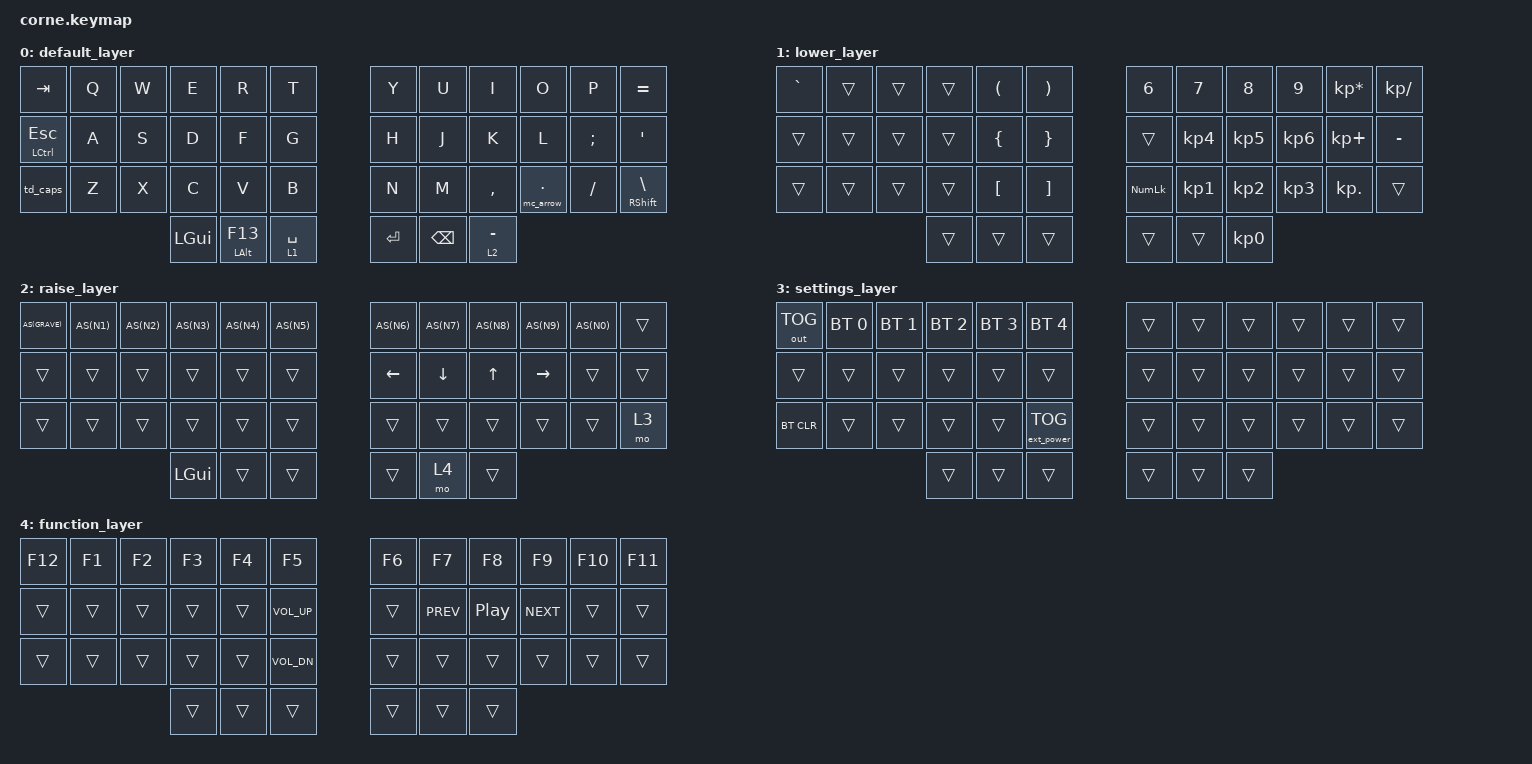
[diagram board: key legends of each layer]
/*
 * Copyright (c) 2020 The ZMK Contributors
 *
 * SPDX-License-Identifier: MIT
 */

#include <behaviors.dtsi>
#include <dt-bindings/zmk/keys.h>
#include <dt-bindings/zmk/bt.h>
#include <dt-bindings/zmk/outputs.h>
#include <dt-bindings/zmk/ext_power.h>

#define AS(keycode) &as LS(keycode) keycode

/ {
	behaviors {
		ht_arr: hold_tap_arrow {
			compatible = "zmk,behavior-hold-tap";
			label = "HT_ARR";
			#binding-cells = <2>;
			tapping-term-ms = <200>;
			flavor = "tap-preferred";
			bindings = <&mc_arrow>, <&kp>;
		};
		td_caps: tap_dance_caps_word {
			compatible = "zmk,behavior-tap-dance";
			label = "TD_CAPS";
			#binding-cells = <0>;
			tapping-term-ms = <150>;
			bindings = <&kp LSHFT>, <&caps_word>;
		};
		as: auto_shift {
			compatible = "zmk,behavior-hold-tap";
			label = "AUTO_SHIFT";
			#binding-cells = <2>;
			tapping_term_ms = <250>;
			quick_tap_ms = <0>;
			flavor = "tap-preferred";
			bindings = <&kp>, <&kp>;
		};
	};
	macros {
		ZMK_MACRO(mc_arrow,
			wait-ms = <50>;
			tap-ms = <50>;
			bindings 
				= <&macro_tap &kp MINUS>
				, <&macro_press &kp LSHFT>
				, <&macro_tap &kp DOT>
				, <&macro_release &kp LSHFT>
				;
		)
	};
	keymap {
		compatible = "zmk,keymap";

		default_layer {
			bindings = <
	&kp TAB      &kp Q &kp W &kp E &kp R &kp T	&kp Y &kp U &kp I     &kp O         &kp P    &kp EQUAL
	&mt LCTRL ESC &kp A &kp S &kp D &kp F &kp G	&kp H &kp J &kp K     &kp L         &kp SEMI &kp SQT
	&td_caps     &kp Z &kp X &kp C &kp V &kp B	&kp N &kp M &kp COMMA &ht_arr 0 DOT &kp FSLH &mt RSHFT BSLH
	        &kp LGUI &mt LALT F13 &lt 1 SPACE	&kp RET &kp BSPC &lt 2 MINUS
			>;
		};
		lower_layer {
			bindings = <
	&kp GRAVE &trans &trans &trans &kp LPAR &kp RPAR	&kp N6     &kp N7    &kp N8    &kp N9    &kp KP_MULTIPLY &kp KP_DIVIDE
	&trans    &trans &trans &trans &kp LBRC &kp RBRC	&trans     &kp KP_N4 &kp KP_N5 &kp KP_N6 &kp KP_PLUS     &kp MINUS
	&trans    &trans &trans &trans &kp LBKT &kp RBKT	&kp KP_NUM &kp KP_N1 &kp KP_N2 &kp KP_N3 &kp KP_DOT      &trans
	                            &trans &trans &trans	&trans     &trans    &kp KP_N0
			>;
		};

		raise_layer {
			bindings = <
	AS(GRAVE) AS(N1) AS(N2) AS(N3) AS(N4) AS(N5)	AS(N6)   AS(N7)   AS(N8) AS(N9)    AS(N0) &trans
	&trans    &trans &trans &trans &trans &trans	&kp LEFT &kp DOWN &kp UP &kp RIGHT &trans &trans
	&trans    &trans &trans &trans &trans &trans	&trans   &trans   &trans &trans    &trans &mo 3
	                      &kp LGUI &trans &trans	&trans   &mo 4    &trans
			>;
		};

		settings_layer {
			bindings = <
	&out OUT_TOG &bt BT_SEL 0 &bt BT_SEL 1 &bt BT_SEL 2 &bt BT_SEL 3 &bt BT_SEL 4     	&trans &trans &trans &trans &trans &trans
	&trans       &trans       &trans       &trans       &trans       &trans           	&trans &trans &trans &trans &trans &trans
	&bt BT_CLR   &trans       &trans       &trans       &trans       &ext_power EP_TOG	&trans &trans &trans &trans &trans &trans 
	                                                              &trans &trans &trans	&trans &trans &trans
			>;
		};
		function_layer {
			bindings = <
	&kp F12 &kp F1 &kp F2 &kp F3 &kp F4 &kp F5      	&kp F6 &kp F7     &kp F8   &kp F9     &kp F10 &kp F11
	&trans  &trans &trans &trans &trans &kp C_VOL_UP	&trans &kp C_PREV &kp C_PP &kp C_NEXT &trans  &trans
	&trans  &trans &trans &trans &trans &kp C_VOL_DN	&trans &trans     &trans   &trans     &trans  &trans 
	                            &trans &trans &trans	&trans &trans &trans
			>;
		};
	};
};
